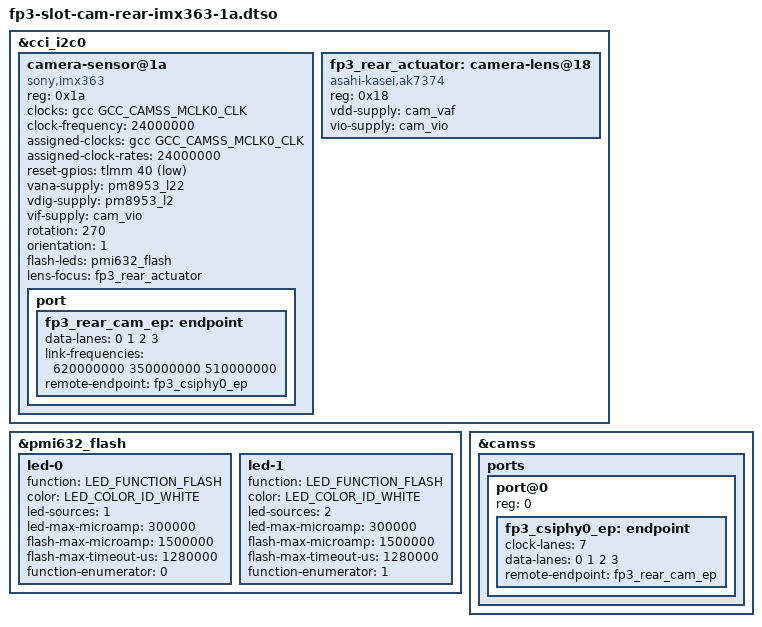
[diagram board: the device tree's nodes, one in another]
// SPDX-License-Identifier: BSD-3-Clause
/*
 * Fairphone 3 rear camera module: Sony IMX363 (12MP) behind an
 * Asahi Kasei AK7374 voice coil motor, on CSIPHY0.
 *
 * Applied by drivers/misc/fp3_module_slot.c when the rear slot answers
 * at 0x1a with chip ID 0x0363.
 *
 * This module is also the one wired to the PMI632 flash LEDs, so the
 * flash controller is enabled here rather than in the base device tree —
 * the Fairphone 3+ camera module does not use it.
 */
/dts-v1/;
/plugin/;

#include <dt-bindings/clock/qcom,gcc-msm8953.h>
#include <dt-bindings/gpio/gpio.h>
#include <dt-bindings/leds/common.h>

&cci_i2c0 {
	#address-cells = <1>;
	#size-cells = <0>;

	camera-sensor@1a {
		compatible = "sony,imx363";
		reg = <0x1a>;

		clocks = <&gcc GCC_CAMSS_MCLK0_CLK>;
		clock-frequency = <24000000>;
		assigned-clocks = <&gcc GCC_CAMSS_MCLK0_CLK>;
		assigned-clock-rates = <24000000>;

		reset-gpios = <&tlmm 40 GPIO_ACTIVE_LOW>;

		vana-supply = <&pm8953_l22>;
		vdig-supply = <&pm8953_l2>;
		vif-supply = <&cam_vio>;

		rotation = <270>;
		orientation = <1>;

		flash-leds = <&pmi632_flash>;
		lens-focus = <&fp3_rear_actuator>;

		port {
			fp3_rear_cam_ep: endpoint {
				data-lanes = <0 1 2 3>;
				link-frequencies = /bits/ 64 <620000000 350000000 510000000>;
				remote-endpoint = <&fp3_csiphy0_ep>;
			};
		};
	};

	fp3_rear_actuator: camera-lens@18 {
		compatible = "asahi-kasei,ak7374";
		reg = <0x18>;

		vdd-supply = <&cam_vaf>;
		vio-supply = <&cam_vio>;
	};
};

&pmi632_flash {
	status = "okay";

	led-0 {
		function = LED_FUNCTION_FLASH;
		color = <LED_COLOR_ID_WHITE>;
		led-sources = <1>;
		led-max-microamp = <300000>;
		flash-max-microamp = <1500000>;
		flash-max-timeout-us = <1280000>;
		function-enumerator = <0>;
	};

	led-1 {
		function = LED_FUNCTION_FLASH;
		color = <LED_COLOR_ID_WHITE>;
		led-sources = <2>;
		led-max-microamp = <300000>;
		flash-max-microamp = <1500000>;
		flash-max-timeout-us = <1280000>;
		function-enumerator = <1>;
	};
};

&camss {
	ports {
		#address-cells = <1>;
		#size-cells = <0>;

		port@0 {
			reg = <0>;

			fp3_csiphy0_ep: endpoint {
				clock-lanes = <7>;
				data-lanes = <0 1 2 3>;
				remote-endpoint = <&fp3_rear_cam_ep>;
			};
		};
	};
};
